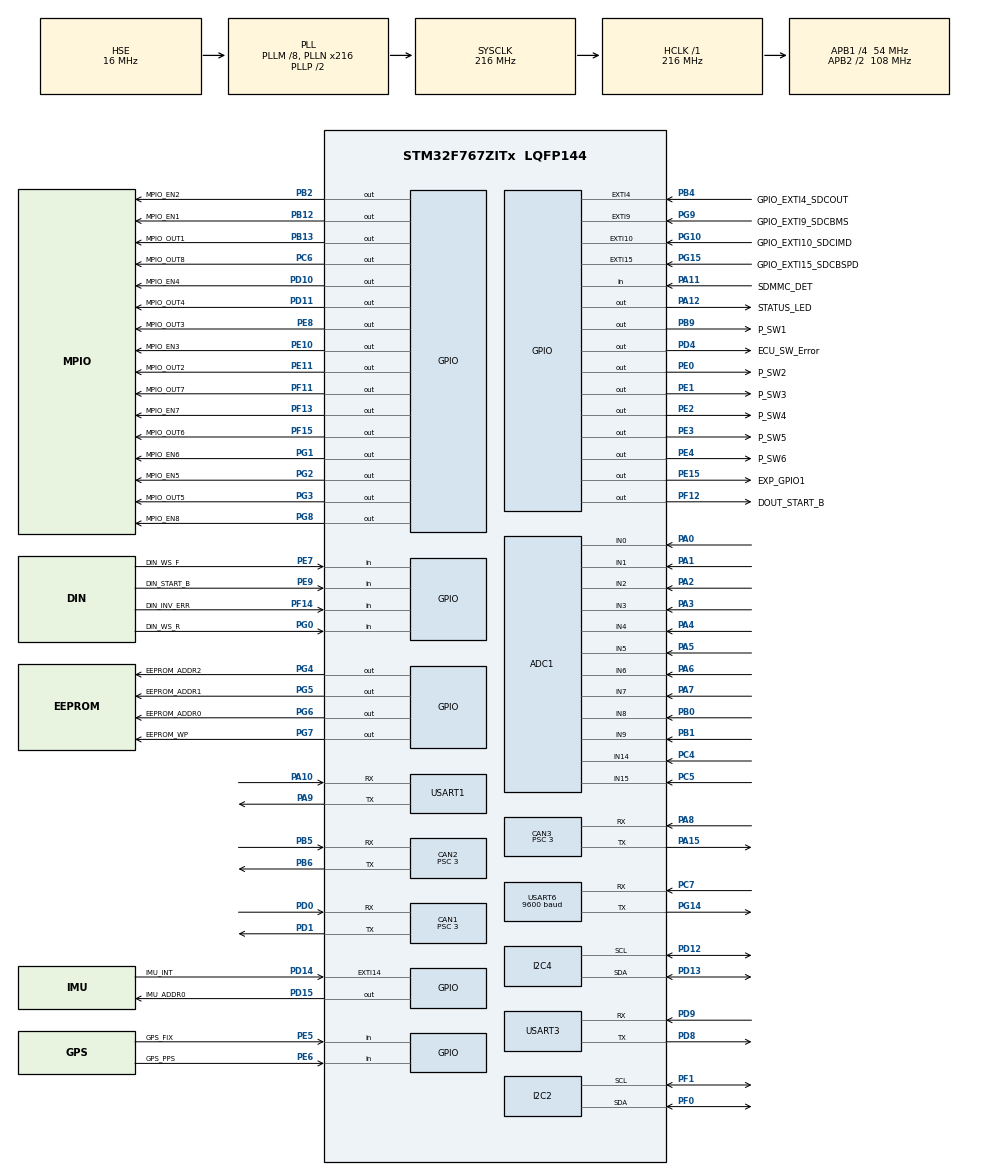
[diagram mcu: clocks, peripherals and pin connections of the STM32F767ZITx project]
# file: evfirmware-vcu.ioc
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ADC1.Channel-0\#ChannelRegularConversion=ADC_CHANNEL_0
ADC1.Channel-1\#ChannelRegularConversion=ADC_CHANNEL_1
ADC1.Channel-10\#ChannelRegularConversion=ADC_CHANNEL_14
ADC1.Channel-11\#ChannelRegularConversion=ADC_CHANNEL_15
ADC1.Channel-2\#ChannelRegularConversion=ADC_CHANNEL_2
ADC1.Channel-3\#ChannelRegularConversion=ADC_CHANNEL_3
ADC1.Channel-4\#ChannelRegularConversion=ADC_CHANNEL_4
ADC1.Channel-5\#ChannelRegularConversion=ADC_CHANNEL_5
ADC1.Channel-6\#ChannelRegularConversion=ADC_CHANNEL_6
ADC1.Channel-7\#ChannelRegularConversion=ADC_CHANNEL_7
ADC1.Channel-8\#ChannelRegularConversion=ADC_CHANNEL_8
ADC1.Channel-9\#ChannelRegularConversion=ADC_CHANNEL_9
ADC1.ClockPrescaler=ADC_CLOCK_SYNC_PCLK_DIV8
ADC1.ContinuousConvMode=ENABLE
ADC1.NbrOfConversion=12
ADC1.NbrOfConversionFlag=1
ADC1.Rank-0\#ChannelRegularConversion=1
ADC1.Rank-1\#ChannelRegularConversion=2
ADC1.Rank-10\#ChannelRegularConversion=11
ADC1.Rank-11\#ChannelRegularConversion=12
ADC1.Rank-2\#ChannelRegularConversion=3
ADC1.Rank-3\#ChannelRegularConversion=4
ADC1.Rank-4\#ChannelRegularConversion=5
ADC1.Rank-5\#ChannelRegularConversion=6
ADC1.Rank-6\#ChannelRegularConversion=7
ADC1.Rank-7\#ChannelRegularConversion=8
ADC1.Rank-8\#ChannelRegularConversion=9
ADC1.Rank-9\#ChannelRegularConversion=10
ADC1.SamplingTime-0\#ChannelRegularConversion=ADC_SAMPLETIME_480CYCLES
ADC1.SamplingTime-1\#ChannelRegularConversion=ADC_SAMPLETIME_480CYCLES
ADC1.SamplingTime-10\#ChannelRegularConversion=ADC_SAMPLETIME_480CYCLES
ADC1.SamplingTime-11\#ChannelRegularConversion=ADC_SAMPLETIME_480CYCLES
ADC1.SamplingTime-2\#ChannelRegularConversion=ADC_SAMPLETIME_480CYCLES
ADC1.SamplingTime-3\#ChannelRegularConversion=ADC_SAMPLETIME_480CYCLES
ADC1.SamplingTime-4\#ChannelRegularConversion=ADC_SAMPLETIME_480CYCLES
ADC1.SamplingTime-5\#ChannelRegularConversion=ADC_SAMPLETIME_480CYCLES
ADC1.SamplingTime-6\#ChannelRegularConversion=ADC_SAMPLETIME_480CYCLES
ADC1.SamplingTime-7\#ChannelRegularConversion=ADC_SAMPLETIME_480CYCLES
ADC1.SamplingTime-8\#ChannelRegularConversion=ADC_SAMPLETIME_480CYCLES
ADC1.SamplingTime-9\#ChannelRegularConversion=ADC_SAMPLETIME_480CYCLES
ADC1.ScanConvMode=ADC_SCAN_ENABLE
ADC1.master=1
CAN1.BS1=CAN_BS1_15TQ
CAN1.BS2=CAN_BS2_2TQ
CAN1.CalculateBaudRate=1000000
CAN1.CalculateTimeBit=1000
CAN1.CalculateTimeQuantum=55.55555555555556
CAN1.Prescaler=3
CAN2.BS1=CAN_BS1_15TQ
CAN2.BS2=CAN_BS2_2TQ
CAN2.CalculateBaudRate=1000000
CAN2.CalculateTimeBit=1000
CAN2.CalculateTimeQuantum=55.55555555555556
CAN2.Prescaler=3
CAN3.BS1=CAN_BS1_15TQ
CAN3.BS2=CAN_BS2_2TQ
CAN3.CalculateBaudRate=1000000
CAN3.CalculateTimeBit=1000
CAN3.CalculateTimeQuantum=55.55555555555556
CAN3.Prescaler=3
CRC.InputDataFormat=CRC_INPUTDATA_FORMAT_BYTES
Dma.ADC1.0.Direction=DMA_PERIPH_TO_MEMORY
Dma.ADC1.0.FIFOMode=DMA_FIFOMODE_DISABLE
Dma.ADC1.0.Instance=DMA2_Stream0
Dma.ADC1.0.MemDataAlignment=DMA_MDATAALIGN_HALFWORD
Dma.ADC1.0.MemInc=DMA_MINC_ENABLE
Dma.ADC1.0.Mode=DMA_CIRCULAR
Dma.ADC1.0.PeriphDataAlignment=DMA_PDATAALIGN_HALFWORD
Dma.ADC1.0.PeriphInc=DMA_PINC_DISABLE
Dma.ADC1.0.Priority=DMA_PRIORITY_LOW
Dma.I2C2_RX.8.Direction=DMA_PERIPH_TO_MEMORY
Dma.I2C2_RX.8.FIFOMode=DMA_FIFOMODE_DISABLE
Dma.I2C2_RX.8.Instance=DMA1_Stream2
Dma.I2C2_RX.8.MemDataAlignment=DMA_MDATAALIGN_BYTE
Dma.I2C2_RX.8.MemInc=DMA_MINC_ENABLE
Dma.I2C2_RX.8.Mode=DMA_NORMAL
Dma.I2C2_RX.8.PeriphDataAlignment=DMA_PDATAALIGN_BYTE
Dma.I2C2_RX.8.PeriphInc=DMA_PINC_DISABLE
Dma.I2C2_RX.8.Priority=DMA_PRIORITY_LOW
Dma.I2C2_TX.7.Direction=DMA_MEMORY_TO_PERIPH
Dma.I2C2_TX.7.FIFOMode=DMA_FIFOMODE_DISABLE
Dma.I2C2_TX.7.Instance=DMA1_Stream4
Dma.I2C2_TX.7.MemDataAlignment=DMA_MDATAALIGN_BYTE
Dma.I2C2_TX.7.MemInc=DMA_MINC_ENABLE
Dma.I2C2_TX.7.Mode=DMA_NORMAL
Dma.I2C2_TX.7.PeriphDataAlignment=DMA_PDATAALIGN_BYTE
Dma.I2C2_TX.7.PeriphInc=DMA_PINC_DISABLE
Dma.I2C2_TX.7.Priority=DMA_PRIORITY_LOW
Dma.Request0=ADC1
Dma.Request1=USART1_RX
Dma.Request2=USART1_TX
Dma.Request3=USART3_RX
Dma.Request4=USART3_TX
Dma.Request5=USART6_RX
Dma.Request6=USART6_TX
Dma.Request7=I2C2_TX
Dma.Request8=I2C2_RX
Dma.USART1_RX.1.Direction=DMA_PERIPH_TO_MEMORY
Dma.USART1_RX.1.FIFOMode=DMA_FIFOMODE_DISABLE
Dma.USART1_RX.1.Instance=DMA2_Stream2
Dma.USART1_RX.1.MemDataAlignment=DMA_MDATAALIGN_BYTE
Dma.USART1_RX.1.MemInc=DMA_MINC_ENABLE
Dma.USART1_RX.1.Mode=DMA_NORMAL
Dma.USART1_RX.1.PeriphDataAlignment=DMA_PDATAALIGN_BYTE
Dma.USART1_RX.1.PeriphInc=DMA_PINC_DISABLE
Dma.USART1_RX.1.Priority=DMA_PRIORITY_LOW
Dma.USART1_TX.2.Direction=DMA_MEMORY_TO_PERIPH
Dma.USART1_TX.2.FIFOMode=DMA_FIFOMODE_DISABLE
Dma.USART1_TX.2.Instance=DMA2_Stream7
Dma.USART1_TX.2.MemDataAlignment=DMA_MDATAALIGN_BYTE
Dma.USART1_TX.2.MemInc=DMA_MINC_ENABLE
Dma.USART1_TX.2.Mode=DMA_NORMAL
Dma.USART1_TX.2.PeriphDataAlignment=DMA_PDATAALIGN_BYTE
Dma.USART1_TX.2.PeriphInc=DMA_PINC_DISABLE
Dma.USART1_TX.2.Priority=DMA_PRIORITY_LOW
Dma.USART3_RX.3.Direction=DMA_PERIPH_TO_MEMORY
Dma.USART3_RX.3.FIFOMode=DMA_FIFOMODE_DISABLE
Dma.USART3_RX.3.Instance=DMA1_Stream1
Dma.USART3_RX.3.MemDataAlignment=DMA_MDATAALIGN_BYTE
Dma.USART3_RX.3.MemInc=DMA_MINC_ENABLE
Dma.USART3_RX.3.Mode=DMA_NORMAL
Dma.USART3_RX.3.PeriphDataAlignment=DMA_PDATAALIGN_BYTE
Dma.USART3_RX.3.PeriphInc=DMA_PINC_DISABLE
Dma.USART3_RX.3.Priority=DMA_PRIORITY_LOW
Dma.USART3_TX.4.Direction=DMA_MEMORY_TO_PERIPH
Dma.USART3_TX.4.FIFOMode=DMA_FIFOMODE_DISABLE
Dma.USART3_TX.4.Instance=DMA1_Stream3
Dma.USART3_TX.4.MemDataAlignment=DMA_MDATAALIGN_BYTE
Dma.USART3_TX.4.MemInc=DMA_MINC_ENABLE
Dma.USART3_TX.4.Mode=DMA_NORMAL
Dma.USART3_TX.4.PeriphDataAlignment=DMA_PDATAALIGN_BYTE
Dma.USART3_TX.4.PeriphInc=DMA_PINC_DISABLE
Dma.USART3_TX.4.Priority=DMA_PRIORITY_LOW
Dma.USART6_RX.5.Direction=DMA_PERIPH_TO_MEMORY
Dma.USART6_RX.5.FIFOMode=DMA_FIFOMODE_DISABLE
Dma.USART6_RX.5.Instance=DMA2_Stream1
Dma.USART6_RX.5.MemDataAlignment=DMA_MDATAALIGN_BYTE
Dma.USART6_RX.5.MemInc=DMA_MINC_ENABLE
Dma.USART6_RX.5.Mode=DMA_NORMAL
Dma.USART6_RX.5.PeriphDataAlignment=DMA_PDATAALIGN_BYTE
Dma.USART6_RX.5.PeriphInc=DMA_PINC_DISABLE
Dma.USART6_RX.5.Priority=DMA_PRIORITY_LOW
Dma.USART6_TX.6.Direction=DMA_MEMORY_TO_PERIPH
Dma.USART6_TX.6.FIFOMode=DMA_FIFOMODE_DISABLE
Dma.USART6_TX.6.Instance=DMA2_Stream6
Dma.USART6_TX.6.MemDataAlignment=DMA_MDATAALIGN_BYTE
Dma.USART6_TX.6.MemInc=DMA_MINC_ENABLE
Dma.USART6_TX.6.Mode=DMA_NORMAL
Dma.USART6_TX.6.PeriphDataAlignment=DMA_PDATAALIGN_BYTE
Dma.USART6_TX.6.PeriphInc=DMA_PINC_DISABLE
Dma.USART6_TX.6.Priority=DMA_PRIORITY_LOW
I2C2.Timing=0x20404768
I2C4.Timing=0x20404768
Mcu.Family=STM32F7
Mcu.Name=STM32F767ZITx
Mcu.Package=LQFP144
NVIC.CAN1_RX0_IRQn=true\:6\:0\:true\:false\:true\:true\:true\:true
NVIC.CAN1_RX1_IRQn=true\:6\:0\:true\:false\:true\:true\:true\:true
NVIC.CAN1_TX_IRQn=true\:6\:0\:true\:false\:true\:true\:true\:true
NVIC.CAN2_RX0_IRQn=true\:6\:0\:true\:false\:true\:true\:true\:true
NVIC.CAN2_RX1_IRQn=true\:6\:0\:true\:false\:true\:true\:true\:true
NVIC.CAN2_TX_IRQn=true\:6\:0\:true\:false\:true\:true\:true\:true
NVIC.CAN3_RX0_IRQn=true\:6\:0\:true\:false\:true\:true\:true\:true
NVIC.CAN3_RX1_IRQn=true\:6\:0\:true\:false\:true\:true\:true\:true
NVIC.CAN3_TX_IRQn=true\:6\:0\:true\:false\:true\:true\:true\:true
NVIC.DMA1_Stream1_IRQn=true\:6\:0\:true\:false\:true\:false\:true\:true
NVIC.DMA1_Stream2_IRQn=true\:0\:0\:false\:false\:true\:false\:true\:true
NVIC.DMA1_Stream3_IRQn=true\:6\:0\:true\:false\:true\:false\:true\:true
NVIC.DMA1_Stream4_IRQn=true\:0\:0\:false\:false\:true\:false\:true\:true
NVIC.DMA2_Stream0_IRQn=true\:6\:0\:true\:false\:true\:false\:true\:true
NVIC.DMA2_Stream1_IRQn=true\:6\:0\:true\:false\:true\:false\:true\:true
NVIC.DMA2_Stream2_IRQn=true\:6\:0\:true\:false\:true\:false\:true\:true
NVIC.DMA2_Stream6_IRQn=true\:6\:0\:true\:false\:true\:false\:true\:true
NVIC.DMA2_Stream7_IRQn=true\:6\:0\:true\:false\:true\:false\:true\:true
NVIC.EXTI15_10_IRQn=true\:6\:0\:true\:false\:true\:true\:true\:true
NVIC.EXTI4_IRQn=true\:6\:0\:true\:false\:true\:true\:true\:true
NVIC.EXTI9_5_IRQn=true\:6\:0\:true\:false\:true\:true\:true\:true
NVIC.PriorityGroup=NVIC_PRIORITYGROUP_4
NVIC.TIM1_UP_TIM10_IRQn=true\:0\:0\:false\:false\:true\:false\:true\:true
NVIC.TIM2_IRQn=true\:5\:0\:true\:false\:true\:true\:true\:true
NVIC.TIM3_IRQn=true\:5\:0\:true\:false\:true\:true\:true\:true
NVIC.TimeBase=TIM1_UP_TIM10_IRQn
NVIC.TimeBaseIP=TIM1
NVIC.USART1_IRQn=true\:7\:0\:true\:false\:true\:true\:true\:true
NVIC.USART3_IRQn=true\:7\:0\:true\:false\:true\:true\:true\:true
NVIC.USART6_IRQn=true\:7\:0\:true\:false\:true\:true\:true\:true
PA0/WKUP.Signal=ADCx_IN0
PA1.Signal=ADCx_IN1
PA10.GPIO_PuPd=GPIO_PULLUP
PA10.Mode=Asynchronous
PA10.Signal=USART1_RX
PA11.GPIO_Label=SDMMC_DET
PA11.Signal=GPIO_Input
PA12.GPIO_Label=STATUS_LED
PA12.Signal=GPIO_Output
PA13.Mode=Trace_Asynchronous_SW
PA13.Signal=SYS_JTMS-SWDIO
PA14.Mode=Trace_Asynchronous_SW
PA14.Signal=SYS_JTCK-SWCLK
PA15.Mode=CAN_Activate
PA15.Signal=CAN3_TX
PA2.Signal=ADCx_IN2
PA3.Signal=ADCx_IN3
PA4.Signal=ADCx_IN4
PA5.Signal=ADCx_IN5
PA6.Signal=ADCx_IN6
PA7.Signal=ADCx_IN7
PA8.Mode=CAN_Activate
PA8.Signal=CAN3_RX
PA9.GPIO_PuPd=GPIO_PULLUP
PA9.Mode=Asynchronous
PA9.Signal=USART1_TX
PB0.Signal=ADCx_IN8
PB1.Signal=ADCx_IN9
PB12.GPIO_Label=MPIO_EN1
PB12.Signal=GPIO_Output
PB13.GPIO_Label=MPIO_OUT1
PB13.Signal=GPIO_Output
PB2.GPIO_Label=MPIO_EN2
PB2.Signal=GPIO_Output
PB3.Mode=Trace_Asynchronous_SW
PB3.Signal=SYS_JTDO-SWO
PB4.GPIO_Label=GPIO_EXTI4_SDCOUT
PB4.Signal=GPXTI4
PB5.Mode=CAN_Activate
PB5.Signal=CAN2_RX
PB6.Mode=CAN_Activate
PB6.Signal=CAN2_TX
PB9.GPIO_Label=P_SW1
PB9.Signal=GPIO_Output
PC14/OSC32_IN.Mode=LSE-External-Oscillator
PC14/OSC32_IN.Signal=RCC_OSC32_IN
PC15/OSC32_OUT.Mode=LSE-External-Oscillator
PC15/OSC32_OUT.Signal=RCC_OSC32_OUT
PC4.Signal=ADCx_IN14
PC5.Signal=ADCx_IN15
PC6.GPIO_Label=MPIO_OUT8
PC6.Signal=GPIO_Output
PC7.Mode=Asynchronous
PC7.Signal=USART6_RX
PD0.Mode=CAN_Activate
PD0.Signal=CAN1_RX
PD1.Mode=CAN_Activate
PD1.Signal=CAN1_TX
PD10.GPIO_Label=MPIO_EN4
PD10.Signal=GPIO_Output
PD11.GPIO_Label=MPIO_OUT4
PD11.Signal=GPIO_Output
PD12.GPIO_Pu=GPIO_PULLUP
PD12.Mode=I2C
PD12.Signal=I2C4_SCL
PD13.GPIO_Pu=GPIO_PULLUP
PD13.Mode=I2C
PD13.Signal=I2C4_SDA
PD14.GPIO_Label=IMU_INT
PD14.Signal=GPXTI14
PD15.GPIO_Label=IMU_ADDR0
PD15.Signal=GPIO_Output
PD4.GPIO_Label=ECU_SW_Error
PD4.Signal=GPIO_Output
PD8.Mode=Asynchronous
PD8.Signal=USART3_TX
PD9.Mode=Asynchronous
PD9.Signal=USART3_RX
PE0.GPIO_Label=P_SW2
PE0.Signal=GPIO_Output
PE1.GPIO_Label=P_SW3
PE1.Signal=GPIO_Output
PE10.GPIO_Label=MPIO_EN3
PE10.Signal=GPIO_Output
PE11.GPIO_Label=MPIO_OUT2
PE11.Signal=GPIO_Output
PE15.GPIO_Label=EXP_GPIO1
PE15.Signal=GPIO_Output
PE2.GPIO_Label=P_SW4
PE2.Signal=GPIO_Output
PE3.GPIO_Label=P_SW5
PE3.Signal=GPIO_Output
PE4.GPIO_Label=P_SW6
PE4.Signal=GPIO_Output
PE5.GPIO_Label=GPS_FIX
PE5.Signal=GPIO_Input
PE6.GPIO_Label=GPS_PPS
PE6.Signal=GPIO_Input
PE7.GPIO_Label=DIN_WS_F
PE7.Signal=GPIO_Input
PE8.GPIO_Label=MPIO_OUT3
PE8.Signal=GPIO_Output
PE9.GPIO_Label=DIN_START_B
PE9.Signal=GPIO_Input
PF0.GPIO_Pu=GPIO_PULLUP
PF0.Mode=I2C
PF0.Signal=I2C2_SDA
PF1.GPIO_Pu=GPIO_PULLUP
PF1.Mode=I2C
PF1.Signal=I2C2_SCL
PF11.GPIO_Label=MPIO_OUT7
PF11.Signal=GPIO_Output
PF12.GPIO_Label=DOUT_START_B
PF12.Signal=GPIO_Output
PF13.GPIO_Label=MPIO_EN7
PF13.Signal=GPIO_Output
PF14.GPIO_Label=DIN_INV_ERR
PF14.Signal=GPIO_Input
PF15.GPIO_Label=MPIO_OUT6
PF15.Signal=GPIO_Output
PG0.GPIO_Label=DIN_WS_R
PG0.Signal=GPIO_Input
PG1.GPIO_Label=MPIO_EN6
PG1.Signal=GPIO_Output
PG10.GPIO_Label=GPIO_EXTI10_SDCIMD
PG10.Signal=GPXTI10
PG14.Mode=Asynchronous
PG14.Signal=USART6_TX
PG15.GPIO_Label=GPIO_EXTI15_SDCBSPD
PG15.Signal=GPXTI15
PG2.GPIO_Label=MPIO_EN5
PG2.Signal=GPIO_Output
PG3.GPIO_Label=MPIO_OUT5
PG3.Signal=GPIO_Output
PG4.GPIO_Label=EEPROM_ADDR2
PG4.Signal=GPIO_Output
PG5.GPIO_Label=EEPROM_ADDR1
PG5.Signal=GPIO_Output
PG6.GPIO_Label=EEPROM_ADDR0
PG6.Signal=GPIO_Output
PG7.GPIO_Label=EEPROM_WP
PG7.Signal=GPIO_Output
PG8.GPIO_Label=MPIO_EN8
PG8.Signal=GPIO_Output
PG9.GPIO_Label=GPIO_EXTI9_SDCBMS
PG9.Signal=GPXTI9
PH0/OSC_IN.Mode=HSE-External-Oscillator
PH0/OSC_IN.Signal=RCC_OSC_IN
PH1/OSC_OUT.Mode=HSE-External-Oscillator
PH1/OSC_OUT.Signal=RCC_OSC_OUT
ProjectManager.HeapSize=0x200
ProjectManager.StackSize=0x400
ProjectManager.TargetToolchain=STM32CubeIDE
RCC.AHBFreq_Value=216000000
RCC.APB1CLKDivider=RCC_HCLK_DIV4
RCC.APB1Freq_Value=54000000
RCC.APB1TimFreq_Value=108000000
RCC.APB2CLKDivider=RCC_HCLK_DIV2
RCC.APB2Freq_Value=108000000
RCC.APB2TimFreq_Value=216000000
RCC.CortexFreq_Value=216000000
RCC.HCLKFreq_Value=216000000
RCC.HSE_VALUE=16000000
RCC.HSI_VALUE=16000000
RCC.PLLM=8
RCC.PLLN=216
RCC.PLLQ=9
RCC.PLLSourceVirtual=RCC_PLLSOURCE_HSE
RCC.SDMMCClockSelection=RCC_SDMMC1CLKSOURCE_CLK48
RCC.SYSCLKFreq_VALUE=216000000
RCC.SYSCLKSource=RCC_SYSCLKSOURCE_PLLCLK
RCC.USBFreq_Value=48000000
RCC.VCOOutputFreq_Value=432000000
SH.ADCx_IN0.0=ADC1_IN0,IN0
SH.ADCx_IN1.0=ADC1_IN1,IN1
SH.ADCx_IN14.0=ADC1_IN14,IN14
SH.ADCx_IN15.0=ADC1_IN15,IN15
SH.ADCx_IN2.0=ADC1_IN2,IN2
SH.ADCx_IN3.0=ADC1_IN3,IN3
SH.ADCx_IN4.0=ADC1_IN4,IN4
SH.ADCx_IN5.0=ADC1_IN5,IN5
SH.ADCx_IN6.0=ADC1_IN6,IN6
SH.ADCx_IN7.0=ADC1_IN7,IN7
SH.ADCx_IN8.0=ADC1_IN8,IN8
SH.ADCx_IN9.0=ADC1_IN9,IN9
TIM2.Period=1079
TIM2.Prescaler=999
TIM3.Period=539
TIM3.Prescaler=99
USART1.VirtualMode-Asynchronous=VM_ASYNC
USART3.VirtualMode-Asynchronous=VM_ASYNC
USART6.BaudRate=9600
USART6.VirtualMode-Asynchronous=VM_ASYNC
VP_CRC_VS_CRC.Mode=CRC_Activate
VP_RTC_VS_RTC_Activate.Mode=RTC_Enabled
VP_SYS_VS_tim1.Mode=TIM1
VP_TIM2_VS_ClockSourceINT.Mode=Internal
VP_TIM3_VS_ClockSourceINT.Mode=Internal
board=custom

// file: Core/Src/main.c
/* USER CODE BEGIN Header */
/**
  ******************************************************************************
  * @file           : main.c
  * @brief          : Main program body
  ******************************************************************************
  * @attention
  *
  * <h2><center>&copy; Copyright (c) 2021 STMicroelectronics.
  * All rights reserved.</center></h2>
  *
  * This software component is licensed by ST under BSD 3-Clause license,
  * the "License"; You may not use this file except in compliance with the
  * License. You may obtain a copy of the License at:
  *                        opensource.org/licenses/BSD-3-Clause
  *
  ******************************************************************************
  */
/* USER CODE END Header */
#include "main.h"

/* USER CODE BEGIN Includes */
#include <stdio.h>
#include <stdbool.h>
#include "FreeRTOS.h"
#include "task.h"

#include "startup/initialize.h"

#include "lib/logging/logging.h"

/* USER CODE END Includes */

ADC_HandleTypeDef hadc1;
DMA_HandleTypeDef hdma_adc1;

CAN_HandleTypeDef hcan1;
CAN_HandleTypeDef hcan2;
CAN_HandleTypeDef hcan3;

CRC_HandleTypeDef hcrc;

I2C_HandleTypeDef hi2c2;
I2C_HandleTypeDef hi2c4;
DMA_HandleTypeDef hdma_i2c2_tx;
DMA_HandleTypeDef hdma_i2c2_rx;

RTC_HandleTypeDef hrtc;

TIM_HandleTypeDef htim2;
TIM_HandleTypeDef htim3;

UART_HandleTypeDef huart1;
UART_HandleTypeDef huart3;
UART_HandleTypeDef huart6;
DMA_HandleTypeDef hdma_usart1_rx;
DMA_HandleTypeDef hdma_usart1_tx;
DMA_HandleTypeDef hdma_usart3_rx;
DMA_HandleTypeDef hdma_usart3_tx;
DMA_HandleTypeDef hdma_usart6_rx;
DMA_HandleTypeDef hdma_usart6_tx;

/* USER CODE BEGIN PV */
static InitData_T initData;
/* USER CODE END PV */

void SystemClock_Config(void);
static void MX_GPIO_Init(void);
static void MX_ADC1_Init(void);
static void MX_CAN1_Init(void);
static void MX_CAN2_Init(void);
static void MX_CAN3_Init(void);
static void MX_I2C4_Init(void);
static void MX_USART1_UART_Init(void);
static void MX_USART3_UART_Init(void);
static void MX_I2C2_Init(void);
static void MX_USART6_UART_Init(void);
static void MX_RTC_Init(void);
static void MX_DMA_Init(void);
static void MX_TIM2_Init(void);
static void MX_CRC_Init(void);
static void MX_TIM3_Init(void);

int main(void)
{

  /* MCU Configuration--------------------------------------------------------*/

  /* Reset of all peripherals, Initializes the Flash interface and the Systick. */
  HAL_Init();

  /* Configure the system clock */
  SystemClock_Config();

  /* Initialize all configured peripherals */
  MX_GPIO_Init();
  MX_ADC1_Init();
  MX_CAN1_Init();
  MX_CAN2_Init();
  MX_CAN3_Init();
  MX_I2C4_Init();
  MX_USART1_UART_Init();
  MX_USART3_UART_Init();
  MX_I2C2_Init();
  MX_USART6_UART_Init();
  MX_RTC_Init();
  MX_DMA_Init();
  MX_TIM2_Init();
  MX_CRC_Init();
  MX_TIM3_Init();
  /* USER CODE BEGIN 2 */

  printf("\n");
  printf("Entering ECU_Init...\n");
  ECU_Init(&initData);

  /* USER CODE END 2 */

  /* Infinite loop */
  while (1)
  {

  }
}

void SystemClock_Config(void)
{
  RCC_OscInitTypeDef RCC_OscInitStruct = {0};
  RCC_ClkInitTypeDef RCC_ClkInitStruct = {0};

  /** Configure LSE Drive Capability
  */
  HAL_PWR_EnableBkUpAccess();

  /** Configure the main internal regulator output voltage
  */
  __HAL_RCC_PWR_CLK_ENABLE();
  __HAL_PWR_VOLTAGESCALING_CONFIG(PWR_REGULATOR_VOLTAGE_SCALE1);

  /** Initializes the RCC Oscillators according to the specified parameters
  * in the RCC_OscInitTypeDef structure.
  */
  RCC_OscInitStruct.OscillatorType = RCC_OSCILLATORTYPE_LSI|RCC_OSCILLATORTYPE_HSE;
  RCC_OscInitStruct.HSEState = RCC_HSE_ON;
  RCC_OscInitStruct.LSIState = RCC_LSI_ON;
  RCC_OscInitStruct.PLL.PLLState = RCC_PLL_ON;
  RCC_OscInitStruct.PLL.PLLSource = RCC_PLLSOURCE_HSE;
  RCC_OscInitStruct.PLL.PLLM = 8;
  RCC_OscInitStruct.PLL.PLLN = 216;
  RCC_OscInitStruct.PLL.PLLP = RCC_PLLP_DIV2;
  RCC_OscInitStruct.PLL.PLLQ = 9;
  RCC_OscInitStruct.PLL.PLLR = 2;
  if (HAL_RCC_OscConfig(&RCC_OscInitStruct) != HAL_OK)
  {
    Error_Handler();
  }

  /** Activate the Over-Drive mode
  */
  if (HAL_PWREx_EnableOverDrive() != HAL_OK)
  {
    Error_Handler();
  }

  /** Initializes the CPU, AHB and APB buses clocks
  */
  RCC_ClkInitStruct.ClockType = RCC_CLOCKTYPE_HCLK|RCC_CLOCKTYPE_SYSCLK
                              |RCC_CLOCKTYPE_PCLK1|RCC_CLOCKTYPE_PCLK2;
  RCC_ClkInitStruct.SYSCLKSource = RCC_SYSCLKSOURCE_PLLCLK;
  RCC_ClkInitStruct.AHBCLKDivider = RCC_SYSCLK_DIV1;
  RCC_ClkInitStruct.APB1CLKDivider = RCC_HCLK_DIV4;
  RCC_ClkInitStruct.APB2CLKDivider = RCC_HCLK_DIV2;

  if (HAL_RCC_ClockConfig(&RCC_ClkInitStruct, FLASH_LATENCY_7) != HAL_OK)
  {
    Error_Handler();
  }
}

static void MX_ADC1_Init(void)
{

  ADC_ChannelConfTypeDef sConfig = {0};

  /** Configure the global features of the ADC (Clock, Resolution, Data Alignment and number of conversion)
  */
  hadc1.Instance = ADC1;
  hadc1.Init.ClockPrescaler = ADC_CLOCK_SYNC_PCLK_DIV8;
  hadc1.Init.Resolution = ADC_RESOLUTION_12B;
  hadc1.Init.ScanConvMode = ADC_SCAN_ENABLE;
  hadc1.Init.ContinuousConvMode = ENABLE;
  hadc1.Init.DiscontinuousConvMode = DISABLE;
  hadc1.Init.ExternalTrigConvEdge = ADC_EXTERNALTRIGCONVEDGE_NONE;
  hadc1.Init.ExternalTrigConv = ADC_SOFTWARE_START;
  hadc1.Init.DataAlign = ADC_DATAALIGN_RIGHT;
  hadc1.Init.NbrOfConversion = 12;
  hadc1.Init.DMAContinuousRequests = DISABLE;
  hadc1.Init.EOCSelection = ADC_EOC_SINGLE_CONV;
  if (HAL_ADC_Init(&hadc1) != HAL_OK)
  {
    Error_Handler();
  }

  /** Configure for the selected ADC regular channel its corresponding rank in the sequencer and its sample time.
  */
  sConfig.Channel = ADC_CHANNEL_0;
  sConfig.Rank = ADC_REGULAR_RANK_1;
  sConfig.SamplingTime = ADC_SAMPLETIME_480CYCLES;
  if (HAL_ADC_ConfigChannel(&hadc1, &sConfig) != HAL_OK)
  {
    Error_Handler();
  }

  /** Configure for the selected ADC regular channel its corresponding rank in the sequencer and its sample time.
  */
  sConfig.Channel = ADC_CHANNEL_1;
  sConfig.Rank = ADC_REGULAR_RANK_2;
  if (HAL_ADC_ConfigChannel(&hadc1, &sConfig) != HAL_OK)
  {
    Error_Handler();
  }

  /** Configure for the selected ADC regular channel its corresponding rank in the sequencer and its sample time.
  */
  sConfig.Channel = ADC_CHANNEL_2;
  sConfig.Rank = ADC_REGULAR_RANK_3;
  if (HAL_ADC_ConfigChannel(&hadc1, &sConfig) != HAL_OK)
  {
    Error_Handler();
  }

  /** Configure for the selected ADC regular channel its corresponding rank in the sequencer and its sample time.
  */
  sConfig.Channel = ADC_CHANNEL_3;
  sConfig.Rank = ADC_REGULAR_RANK_4;
  if (HAL_ADC_ConfigChannel(&hadc1, &sConfig) != HAL_OK)
  {
    Error_Handler();
  }

  /** Configure for the selected ADC regular channel its corresponding rank in the sequencer and its sample time.
  */
  sConfig.Channel = ADC_CHANNEL_4;
  sConfig.Rank = ADC_REGULAR_RANK_5;
  if (HAL_ADC_ConfigChannel(&hadc1, &sConfig) != HAL_OK)
  {
    Error_Handler();
  }

  /** Configure for the selected ADC regular channel its corresponding rank in the sequencer and its sample time.
  */
  sConfig.Channel = ADC_CHANNEL_5;
  sConfig.Rank = ADC_REGULAR_RANK_6;
  if (HAL_ADC_ConfigChannel(&hadc1, &sConfig) != HAL_OK)
  {
    Error_Handler();
  }

  /** Configure for the selected ADC regular channel its corresponding rank in the sequencer and its sample time.
  */
  sConfig.Channel = ADC_CHANNEL_6;
  sConfig.Rank = ADC_REGULAR_RANK_7;
  if (HAL_ADC_ConfigChannel(&hadc1, &sConfig) != HAL_OK)
  {
    Error_Handler();
  }

  /** Configure for the selected ADC regular channel its corresponding rank in the sequencer and its sample time.
  */
  sConfig.Channel = ADC_CHANNEL_7;
  sConfig.Rank = ADC_REGULAR_RANK_8;
  if (HAL_ADC_ConfigChannel(&hadc1, &sConfig) != HAL_OK)
  {
    Error_Handler();
  }

  /** Configure for the selected ADC regular channel its corresponding rank in the sequencer and its sample time.
  */
  sConfig.Channel = ADC_CHANNEL_8;
  sConfig.Rank = ADC_REGULAR_RANK_9;
  if (HAL_ADC_ConfigChannel(&hadc1, &sConfig) != HAL_OK)
  {
    Error_Handler();
  }

  /** Configure for the selected ADC regular channel its corresponding rank in the sequencer and its sample time.
  */
  sConfig.Channel = ADC_CHANNEL_9;
  sConfig.Rank = ADC_REGULAR_RANK_10;
  if (HAL_ADC_ConfigChannel(&hadc1, &sConfig) != HAL_OK)
  {
    Error_Handler();
  }

  /** Configure for the selected ADC regular channel its corresponding rank in the sequencer and its sample time.
  */
  sConfig.Channel = ADC_CHANNEL_14;
  sConfig.Rank = ADC_REGULAR_RANK_11;
  if (HAL_ADC_ConfigChannel(&hadc1, &sConfig) != HAL_OK)
  {
    Error_Handler();
  }

  /** Configure for the selected ADC regular channel its corresponding rank in the sequencer and its sample time.
  */
  sConfig.Channel = ADC_CHANNEL_15;
  sConfig.Rank = ADC_REGULAR_RANK_12;
  if (HAL_ADC_ConfigChannel(&hadc1, &sConfig) != HAL_OK)
  {
    Error_Handler();
  }

}

static void MX_CAN1_Init(void)
{

  hcan1.Instance = CAN1;
  hcan1.Init.Prescaler = 3;
  hcan1.Init.Mode = CAN_MODE_NORMAL;
  hcan1.Init.SyncJumpWidth = CAN_SJW_1TQ;
  hcan1.Init.TimeSeg1 = CAN_BS1_15TQ;
  hcan1.Init.TimeSeg2 = CAN_BS2_2TQ;
  hcan1.Init.TimeTriggeredMode = DISABLE;
  hcan1.Init.AutoBusOff = DISABLE;
  hcan1.Init.AutoWakeUp = DISABLE;
  hcan1.Init.AutoRetransmission = DISABLE;
  hcan1.Init.ReceiveFifoLocked = DISABLE;
  hcan1.Init.TransmitFifoPriority = DISABLE;
  if (HAL_CAN_Init(&hcan1) != HAL_OK)
  {
    Error_Handler();
  }

}

static void MX_CAN2_Init(void)
{

  hcan2.Instance = CAN2;
  hcan2.Init.Prescaler = 3;
  hcan2.Init.Mode = CAN_MODE_NORMAL;
  hcan2.Init.SyncJumpWidth = CAN_SJW_1TQ;
  hcan2.Init.TimeSeg1 = CAN_BS1_15TQ;
  hcan2.Init.TimeSeg2 = CAN_BS2_2TQ;
  hcan2.Init.TimeTriggeredMode = DISABLE;
  hcan2.Init.AutoBusOff = DISABLE;
  hcan2.Init.AutoWakeUp = DISABLE;
  hcan2.Init.AutoRetransmission = DISABLE;
  hcan2.Init.ReceiveFifoLocked = DISABLE;
  hcan2.Init.TransmitFifoPriority = DISABLE;
  if (HAL_CAN_Init(&hcan2) != HAL_OK)
  {
    Error_Handler();
  }

}

static void MX_CAN3_Init(void)
{

  hcan3.Instance = CAN3;
  hcan3.Init.Prescaler = 3;
  hcan3.Init.Mode = CAN_MODE_NORMAL;
  hcan3.Init.SyncJumpWidth = CAN_SJW_1TQ;
  hcan3.Init.TimeSeg1 = CAN_BS1_15TQ;
  hcan3.Init.TimeSeg2 = CAN_BS2_2TQ;
  hcan3.Init.TimeTriggeredMode = DISABLE;
  hcan3.Init.AutoBusOff = DISABLE;
  hcan3.Init.AutoWakeUp = DISABLE;
  hcan3.Init.AutoRetransmission = DISABLE;
  hcan3.Init.ReceiveFifoLocked = DISABLE;
  hcan3.Init.TransmitFifoPriority = DISABLE;
  if (HAL_CAN_Init(&hcan3) != HAL_OK)
  {
    Error_Handler();
  }

}

static void MX_CRC_Init(void)
{

  hcrc.Instance = CRC;
  hcrc.Init.DefaultPolynomialUse = DEFAULT_POLYNOMIAL_ENABLE;
  hcrc.Init.DefaultInitValueUse = DEFAULT_INIT_VALUE_ENABLE;
  hcrc.Init.InputDataInversionMode = CRC_INPUTDATA_INVERSION_NONE;
  hcrc.Init.OutputDataInversionMode = CRC_OUTPUTDATA_INVERSION_DISABLE;
  hcrc.InputDataFormat = CRC_INPUTDATA_FORMAT_BYTES;
  if (HAL_CRC_Init(&hcrc) != HAL_OK)
  {
    Error_Handler();
  }

}

static void MX_I2C2_Init(void)
{

  hi2c2.Instance = I2C2;
  hi2c2.Init.Timing = 0x20404768;
  hi2c2.Init.OwnAddress1 = 0;
  hi2c2.Init.AddressingMode = I2C_ADDRESSINGMODE_7BIT;
  hi2c2.Init.DualAddressMode = I2C_DUALADDRESS_DISABLE;
  hi2c2.Init.OwnAddress2 = 0;
  hi2c2.Init.OwnAddress2Masks = I2C_OA2_NOMASK;
  hi2c2.Init.GeneralCallMode = I2C_GENERALCALL_DISABLE;
  hi2c2.Init.NoStretchMode = I2C_NOSTRETCH_DISABLE;
  if (HAL_I2C_Init(&hi2c2) != HAL_OK)
  {
    Error_Handler();
  }

  /** Configure Analogue filter
  */
  if (HAL_I2CEx_ConfigAnalogFilter(&hi2c2, I2C_ANALOGFILTER_ENABLE) != HAL_OK)
  {
    Error_Handler();
  }

  /** Configure Digital filter
  */
  if (HAL_I2CEx_ConfigDigitalFilter(&hi2c2, 0) != HAL_OK)
  {
    Error_Handler();
  }

}

static void MX_I2C4_Init(void)
{

  hi2c4.Instance = I2C4;
  hi2c4.Init.Timing = 0x20404768;
  hi2c4.Init.OwnAddress1 = 0;
  hi2c4.Init.AddressingMode = I2C_ADDRESSINGMODE_7BIT;
  hi2c4.Init.DualAddressMode = I2C_DUALADDRESS_DISABLE;
  hi2c4.Init.OwnAddress2 = 0;
  hi2c4.Init.OwnAddress2Masks = I2C_OA2_NOMASK;
  hi2c4.Init.GeneralCallMode = I2C_GENERALCALL_DISABLE;
  hi2c4.Init.NoStretchMode = I2C_NOSTRETCH_DISABLE;
  if (HAL_I2C_Init(&hi2c4) != HAL_OK)
  {
    Error_Handler();
  }

  /** Configure Analogue filter
  */
  if (HAL_I2CEx_ConfigAnalogFilter(&hi2c4, I2C_ANALOGFILTER_ENABLE) != HAL_OK)
  {
    Error_Handler();
  }

  /** Configure Digital filter
  */
  if (HAL_I2CEx_ConfigDigitalFilter(&hi2c4, 0) != HAL_OK)
  {
    Error_Handler();
  }

}

static void MX_RTC_Init(void)
{

  /** Initialize RTC Only
  */
  hrtc.Instance = RTC;
  hrtc.Init.HourFormat = RTC_HOURFORMAT_24;
  hrtc.Init.AsynchPrediv = 127;
  hrtc.Init.SynchPrediv = 255;
  hrtc.Init.OutPut = RTC_OUTPUT_DISABLE;
  hrtc.Init.OutPutPolarity = RTC_OUTPUT_POLARITY_HIGH;
  hrtc.Init.OutPutType = RTC_OUTPUT_TYPE_OPENDRAIN;
  if (HAL_RTC_Init(&hrtc) != HAL_OK)
  {
    Error_Handler();
  }

}

static void MX_TIM2_Init(void)
{

  TIM_ClockConfigTypeDef sClockSourceConfig = {0};
  TIM_MasterConfigTypeDef sMasterConfig = {0};

  htim2.Instance = TIM2;
  htim2.Init.Prescaler = 999;
  htim2.Init.CounterMode = TIM_COUNTERMODE_UP;
  htim2.Init.Period = 1079;
  htim2.Init.ClockDivision = TIM_CLOCKDIVISION_DIV1;
  htim2.Init.AutoReloadPreload = TIM_AUTORELOAD_PRELOAD_DISABLE;
  if (HAL_TIM_Base_Init(&htim2) != HAL_OK)
  {
    Error_Handler();
  }
  sClockSourceConfig.ClockSource = TIM_CLOCKSOURCE_INTERNAL;
  if (HAL_TIM_ConfigClockSource(&htim2, &sClockSourceConfig) != HAL_OK)
  {
    Error_Handler();
  }
  sMasterConfig.MasterOutputTrigger = TIM_TRGO_RESET;
  sMasterConfig.MasterSlaveMode = TIM_MASTERSLAVEMODE_DISABLE;
  if (HAL_TIMEx_MasterConfigSynchronization(&htim2, &sMasterConfig) != HAL_OK)
  {
    Error_Handler();
  }

}

static void MX_TIM3_Init(void)
{

  TIM_ClockConfigTypeDef sClockSourceConfig = {0};
  TIM_MasterConfigTypeDef sMasterConfig = {0};

  htim3.Instance = TIM3;
  htim3.Init.Prescaler = 99;
  htim3.Init.CounterMode = TIM_COUNTERMODE_UP;
  htim3.Init.Period = 539;
  htim3.Init.ClockDivision = TIM_CLOCKDIVISION_DIV1;
  htim3.Init.AutoReloadPreload = TIM_AUTORELOAD_PRELOAD_DISABLE;
  if (HAL_TIM_Base_Init(&htim3) != HAL_OK)
  {
    Error_Handler();
  }
  sClockSourceConfig.ClockSource = TIM_CLOCKSOURCE_INTERNAL;
  if (HAL_TIM_ConfigClockSource(&htim3, &sClockSourceConfig) != HAL_OK)
  {
    Error_Handler();
  }
  sMasterConfig.MasterOutputTrigger = TIM_TRGO_RESET;
  sMasterConfig.MasterSlaveMode = TIM_MASTERSLAVEMODE_DISABLE;
  if (HAL_TIMEx_MasterConfigSynchronization(&htim3, &sMasterConfig) != HAL_OK)
  {
    Error_Handler();
  }

}

static void MX_USART1_UART_Init(void)
{

  huart1.Instance = USART1;
  huart1.Init.BaudRate = 115200;
  huart1.Init.WordLength = UART_WORDLENGTH_8B;
  huart1.Init.StopBits = UART_STOPBITS_1;
  huart1.Init.Parity = UART_PARITY_NONE;
  huart1.Init.Mode = UART_MODE_TX_RX;
  huart1.Init.HwFlowCtl = UART_HWCONTROL_NONE;
  huart1.Init.OverSampling = UART_OVERSAMPLING_16;
  huart1.Init.OneBitSampling = UART_ONE_BIT_SAMPLE_DISABLE;
  huart1.AdvancedInit.AdvFeatureInit = UART_ADVFEATURE_NO_INIT;
  if (HAL_UART_Init(&huart1) != HAL_OK)
  {
    Error_Handler();
  }

}

static void MX_USART3_UART_Init(void)
{

  huart3.Instance = USART3;
  huart3.Init.BaudRate = 115200;
  huart3.Init.WordLength = UART_WORDLENGTH_8B;
  huart3.Init.StopBits = UART_STOPBITS_1;
  huart3.Init.Parity = UART_PARITY_NONE;
  huart3.Init.Mode = UART_MODE_TX_RX;
  huart3.Init.HwFlowCtl = UART_HWCONTROL_NONE;
  huart3.Init.OverSampling = UART_OVERSAMPLING_16;
  huart3.Init.OneBitSampling = UART_ONE_BIT_SAMPLE_DISABLE;
  huart3.AdvancedInit.AdvFeatureInit = UART_ADVFEATURE_NO_INIT;
  if (HAL_UART_Init(&huart3) != HAL_OK)
  {
    Error_Handler();
  }

}

static void MX_USART6_UART_Init(void)
{

  huart6.Instance = USART6;
  huart6.Init.BaudRate = 9600;
  huart6.Init.WordLength = UART_WORDLENGTH_8B;
  huart6.Init.StopBits = UART_STOPBITS_1;
  huart6.Init.Parity = UART_PARITY_NONE;
  huart6.Init.Mode = UART_MODE_TX_RX;
  huart6.Init.HwFlowCtl = UART_HWCONTROL_NONE;
  huart6.Init.OverSampling = UART_OVERSAMPLING_16;
  huart6.Init.OneBitSampling = UART_ONE_BIT_SAMPLE_DISABLE;
  huart6.AdvancedInit.AdvFeatureInit = UART_ADVFEATURE_NO_INIT;
  if (HAL_UART_Init(&huart6) != HAL_OK)
  {
    Error_Handler();
  }

}

static void MX_DMA_Init(void)
{

  /* DMA controller clock enable */
  __HAL_RCC_DMA2_CLK_ENABLE();
  __HAL_RCC_DMA1_CLK_ENABLE();

  /* DMA interrupt init */
  /* DMA1_Stream1_IRQn interrupt configuration */
  HAL_NVIC_SetPriority(DMA1_Stream1_IRQn, 6, 0);
  HAL_NVIC_EnableIRQ(DMA1_Stream1_IRQn);
  /* DMA1_Stream2_IRQn interrupt configuration */
  HAL_NVIC_SetPriority(DMA1_Stream2_IRQn, 0, 0);
  HAL_NVIC_EnableIRQ(DMA1_Stream2_IRQn);
  /* DMA1_Stream3_IRQn interrupt configuration */
  HAL_NVIC_SetPriority(DMA1_Stream3_IRQn, 6, 0);
  HAL_NVIC_EnableIRQ(DMA1_Stream3_IRQn);
  /* DMA1_Stream4_IRQn interrupt configuration */
  HAL_NVIC_SetPriority(DMA1_Stream4_IRQn, 0, 0);
  HAL_NVIC_EnableIRQ(DMA1_Stream4_IRQn);
  /* DMA2_Stream0_IRQn interrupt configuration */
  HAL_NVIC_SetPriority(DMA2_Stream0_IRQn, 6, 0);
  HAL_NVIC_EnableIRQ(DMA2_Stream0_IRQn);
  /* DMA2_Stream1_IRQn interrupt configuration */
  HAL_NVIC_SetPriority(DMA2_Stream1_IRQn, 6, 0);
  HAL_NVIC_EnableIRQ(DMA2_Stream1_IRQn);
  /* DMA2_Stream2_IRQn interrupt configuration */
  HAL_NVIC_SetPriority(DMA2_Stream2_IRQn, 6, 0);
  HAL_NVIC_EnableIRQ(DMA2_Stream2_IRQn);
  /* DMA2_Stream6_IRQn interrupt configuration */
  HAL_NVIC_SetPriority(DMA2_Stream6_IRQn, 6, 0);
  HAL_NVIC_EnableIRQ(DMA2_Stream6_IRQn);
  /* DMA2_Stream7_IRQn interrupt configuration */
  HAL_NVIC_SetPriority(DMA2_Stream7_IRQn, 6, 0);
  HAL_NVIC_EnableIRQ(DMA2_Stream7_IRQn);

}

static void MX_GPIO_Init(void)
{
  GPIO_InitTypeDef GPIO_InitStruct = {0};

  /* GPIO Ports Clock Enable */
  __HAL_RCC_GPIOE_CLK_ENABLE();
  __HAL_RCC_GPIOC_CLK_ENABLE();
  __HAL_RCC_GPIOF_CLK_ENABLE();
  __HAL_RCC_GPIOH_CLK_ENABLE();
  __HAL_RCC_GPIOA_CLK_ENABLE();
  __HAL_RCC_GPIOB_CLK_ENABLE();
  __HAL_RCC_GPIOG_CLK_ENABLE();
  __HAL_RCC_GPIOD_CLK_ENABLE();

  /*Configure GPIO pin Output Level */
  HAL_GPIO_WritePin(GPIOE, P_SW4_Pin|P_SW5_Pin|P_SW6_Pin|MPIO_OUT3_Pin
                          |MPIO_EN3_Pin|MPIO_OUT2_Pin|EXP_GPIO1_Pin|P_SW2_Pin
                          |P_SW3_Pin, GPIO_PIN_RESET);

  /*Configure GPIO pin Output Level */
  HAL_GPIO_WritePin(GPIOB, MPIO_EN2_Pin|MPIO_EN1_Pin|MPIO_OUT1_Pin|P_SW1_Pin, GPIO_PIN_RESET);

  /*Configure GPIO pin Output Level */
  HAL_GPIO_WritePin(GPIOF, MPIO_OUT7_Pin|DOUT_START_B_Pin|MPIO_EN7_Pin|MPIO_OUT6_Pin, GPIO_PIN_RESET);

  /*Configure GPIO pin Output Level */
  HAL_GPIO_WritePin(GPIOG, MPIO_EN6_Pin|MPIO_EN5_Pin|MPIO_OUT5_Pin|EEPROM_ADDR2_Pin
                          |EEPROM_ADDR1_Pin|EEPROM_ADDR0_Pin|EEPROM_WP_Pin|MPIO_EN8_Pin, GPIO_PIN_RESET);

  /*Configure GPIO pin Output Level */
  HAL_GPIO_WritePin(GPIOD, MPIO_EN4_Pin|MPIO_OUT4_Pin|IMU_ADDR0_Pin|ECU_SW_Error_Pin, GPIO_PIN_RESET);

  /*Configure GPIO pin Output Level */
  HAL_GPIO_WritePin(MPIO_OUT8_GPIO_Port, MPIO_OUT8_Pin, GPIO_PIN_RESET);

  /*Configure GPIO pin Output Level */
  HAL_GPIO_WritePin(STATUS_LED_GPIO_Port, STATUS_LED_Pin, GPIO_PIN_RESET);

  /*Configure GPIO pins : P_SW4_Pin P_SW5_Pin P_SW6_Pin MPIO_OUT3_Pin
                           MPIO_EN3_Pin MPIO_OUT2_Pin EXP_GPIO1_Pin P_SW2_Pin
                           P_SW3_Pin */
  GPIO_InitStruct.Pin = P_SW4_Pin|P_SW5_Pin|P_SW6_Pin|MPIO_OUT3_Pin
                          |MPIO_EN3_Pin|MPIO_OUT2_Pin|EXP_GPIO1_Pin|P_SW2_Pin
                          |P_SW3_Pin;
  GPIO_InitStruct.Mode = GPIO_MODE_OUTPUT_PP;
  GPIO_InitStruct.Pull = GPIO_NOPULL;
  GPIO_InitStruct.Speed = GPIO_SPEED_FREQ_LOW;
  HAL_GPIO_Init(GPIOE, &GPIO_InitStruct);

  /*Configure GPIO pins : GPS_FIX_Pin GPS_PPS_Pin DIN_WS_F_Pin DIN_START_B_Pin */
  GPIO_InitStruct.Pin = GPS_FIX_Pin|GPS_PPS_Pin|DIN_WS_F_Pin|DIN_START_B_Pin;
  GPIO_InitStruct.Mode = GPIO_MODE_INPUT;
  GPIO_InitStruct.Pull = GPIO_NOPULL;
  HAL_GPIO_Init(GPIOE, &GPIO_InitStruct);

  /*Configure GPIO pins : MPIO_EN2_Pin MPIO_EN1_Pin MPIO_OUT1_Pin P_SW1_Pin */
  GPIO_InitStruct.Pin = MPIO_EN2_Pin|MPIO_EN1_Pin|MPIO_OUT1_Pin|P_SW1_Pin;
  GPIO_InitStruct.Mode = GPIO_MODE_OUTPUT_PP;
  GPIO_InitStruct.Pull = GPIO_NOPULL;
  GPIO_InitStruct.Speed = GPIO_SPEED_FREQ_LOW;
  HAL_GPIO_Init(GPIOB, &GPIO_InitStruct);

  /*Configure GPIO pins : MPIO_OUT7_Pin DOUT_START_B_Pin MPIO_EN7_Pin MPIO_OUT6_Pin */
  GPIO_InitStruct.Pin = MPIO_OUT7_Pin|DOUT_START_B_Pin|MPIO_EN7_Pin|MPIO_OUT6_Pin;
  GPIO_InitStruct.Mode = GPIO_MODE_OUTPUT_PP;
  GPIO_InitStruct.Pull = GPIO_NOPULL;
  GPIO_InitStruct.Speed = GPIO_SPEED_FREQ_LOW;
  HAL_GPIO_Init(GPIOF, &GPIO_InitStruct);

  /*Configure GPIO pin : DIN_INV_ERR_Pin */
  GPIO_InitStruct.Pin = DIN_INV_ERR_Pin;
  GPIO_InitStruct.Mode = GPIO_MODE_INPUT;
  GPIO_InitStruct.Pull = GPIO_NOPULL;
  HAL_GPIO_Init(DIN_INV_ERR_GPIO_Port, &GPIO_InitStruct);

  /*Configure GPIO pin : DIN_WS_R_Pin */
  GPIO_InitStruct.Pin = DIN_WS_R_Pin;
  GPIO_InitStruct.Mode = GPIO_MODE_INPUT;
  GPIO_InitStruct.Pull = GPIO_NOPULL;
  HAL_GPIO_Init(DIN_WS_R_GPIO_Port, &GPIO_InitStruct);

  /*Configure GPIO pins : MPIO_EN6_Pin MPIO_EN5_Pin MPIO_OUT5_Pin EEPROM_ADDR2_Pin
                           EEPROM_ADDR1_Pin EEPROM_ADDR0_Pin EEPROM_WP_Pin MPIO_EN8_Pin */
  GPIO_InitStruct.Pin = MPIO_EN6_Pin|MPIO_EN5_Pin|MPIO_OUT5_Pin|EEPROM_ADDR2_Pin
                          |EEPROM_ADDR1_Pin|EEPROM_ADDR0_Pin|EEPROM_WP_Pin|MPIO_EN8_Pin;
  GPIO_InitStruct.Mode = GPIO_MODE_OUTPUT_PP;
  GPIO_InitStruct.Pull = GPIO_NOPULL;
  GPIO_InitStruct.Speed = GPIO_SPEED_FREQ_LOW;
  HAL_GPIO_Init(GPIOG, &GPIO_InitStruct);

  /*Configure GPIO pins : MPIO_EN4_Pin MPIO_OUT4_Pin IMU_ADDR0_Pin ECU_SW_Error_Pin */
  GPIO_InitStruct.Pin = MPIO_EN4_Pin|MPIO_OUT4_Pin|IMU_ADDR0_Pin|ECU_SW_Error_Pin;
  GPIO_InitStruct.Mode = GPIO_MODE_OUTPUT_PP;
  GPIO_InitStruct.Pull = GPIO_NOPULL;
  GPIO_InitStruct.Speed = GPIO_SPEED_FREQ_LOW;
  HAL_GPIO_Init(GPIOD, &GPIO_InitStruct);

  /*Configure GPIO pin : IMU_INT_Pin */
  GPIO_InitStruct.Pin = IMU_INT_Pin;
  GPIO_InitStruct.Mode = GPIO_MODE_IT_RISING;
  GPIO_InitStruct.Pull = GPIO_NOPULL;
  HAL_GPIO_Init(IMU_INT_GPIO_Port, &GPIO_InitStruct);

  /*Configure GPIO pin : MPIO_OUT8_Pin */
  GPIO_InitStruct.Pin = MPIO_OUT8_Pin;
  GPIO_InitStruct.Mode = GPIO_MODE_OUTPUT_PP;
  GPIO_InitStruct.Pull = GPIO_NOPULL;
  GPIO_InitStruct.Speed = GPIO_SPEED_FREQ_LOW;
  HAL_GPIO_Init(MPIO_OUT8_GPIO_Port, &GPIO_InitStruct);

  /*Configure GPIO pin : SDMMC_DET_Pin */
  GPIO_InitStruct.Pin = SDMMC_DET_Pin;
  GPIO_InitStruct.Mode = GPIO_MODE_INPUT;
  GPIO_InitStruct.Pull = GPIO_NOPULL;
  HAL_GPIO_Init(SDMMC_DET_GPIO_Port, &GPIO_InitStruct);

  /*Configure GPIO pin : STATUS_LED_Pin */
  GPIO_InitStruct.Pin = STATUS_LED_Pin;
  GPIO_InitStruct.Mode = GPIO_MODE_OUTPUT_PP;
  GPIO_InitStruct.Pull = GPIO_NOPULL;
  GPIO_InitStruct.Speed = GPIO_SPEED_FREQ_LOW;
  HAL_GPIO_Init(STATUS_LED_GPIO_Port, &GPIO_InitStruct);

  /*Configure GPIO pins : GPIO_EXTI9_SDCBMS_Pin GPIO_EXTI10_SDCIMD_Pin GPIO_EXTI15_SDCBSPD_Pin */
  GPIO_InitStruct.Pin = GPIO_EXTI9_SDCBMS_Pin|GPIO_EXTI10_SDCIMD_Pin|GPIO_EXTI15_SDCBSPD_Pin;
  GPIO_InitStruct.Mode = GPIO_MODE_IT_RISING;
  GPIO_InitStruct.Pull = GPIO_NOPULL;
  HAL_GPIO_Init(GPIOG, &GPIO_InitStruct);

  /*Configure GPIO pin : GPIO_EXTI4_SDCOUT_Pin */
  GPIO_InitStruct.Pin = GPIO_EXTI4_SDCOUT_Pin;
  GPIO_InitStruct.Mode = GPIO_MODE_IT_RISING;
  GPIO_InitStruct.Pull = GPIO_NOPULL;
  HAL_GPIO_Init(GPIO_EXTI4_SDCOUT_GPIO_Port, &GPIO_InitStruct);

  /* EXTI interrupt init*/
  HAL_NVIC_SetPriority(EXTI4_IRQn, 6, 0);
  HAL_NVIC_EnableIRQ(EXTI4_IRQn);

  HAL_NVIC_SetPriority(EXTI9_5_IRQn, 6, 0);
  HAL_NVIC_EnableIRQ(EXTI9_5_IRQn);

  HAL_NVIC_SetPriority(EXTI15_10_IRQn, 6, 0);
  HAL_NVIC_EnableIRQ(EXTI15_10_IRQn);

}

void HAL_TIM_PeriodElapsedCallback(TIM_HandleTypeDef *htim)
{
  if (htim->Instance == TIM1) {
    HAL_IncTick();
  }
  /* USER CODE BEGIN Callback 1 */

  // Board timer handlers
  TIM_IRQHandler(htim);

  /* USER CODE END Callback 1 */
}

void Error_Handler(void)
{
  __disable_irq();
  while (1)
  {
  }
}
